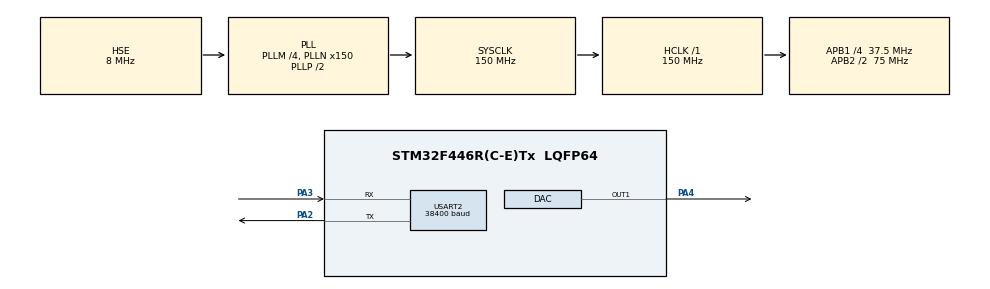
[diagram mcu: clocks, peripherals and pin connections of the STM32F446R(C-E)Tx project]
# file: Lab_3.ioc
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DAC.DAC_Trigger=DAC_TRIGGER_NONE
Mcu.Family=STM32F4
Mcu.Name=STM32F446R(C-E)Tx
Mcu.Package=LQFP64
NVIC.PriorityGroup=NVIC_PRIORITYGROUP_4
NVIC.TIM6_DAC_IRQn=true\:0\:0\:false\:false\:true\:true\:true\:true
NVIC.USART2_IRQn=true\:0\:0\:false\:false\:true\:true\:true\:true
PA2.Mode=Asynchronous
PA2.Signal=USART2_TX
PA3.Mode=Asynchronous
PA3.Signal=USART2_RX
PA4.Signal=COMP_DAC1_group
PH0-OSC_IN.Mode=HSE-External-Oscillator
PH0-OSC_IN.Signal=RCC_OSC_IN
PH1-OSC_OUT.Mode=HSE-External-Oscillator
PH1-OSC_OUT.Signal=RCC_OSC_OUT
ProjectManager.HeapSize=0x200
ProjectManager.StackSize=0x400
ProjectManager.TargetToolchain=STM32CubeIDE
RCC.AHBFreq_Value=150000000
RCC.APB1CLKDivider=RCC_HCLK_DIV4
RCC.APB1Freq_Value=37500000
RCC.APB1TimFreq_Value=75000000
RCC.APB2CLKDivider=RCC_HCLK_DIV2
RCC.APB2Freq_Value=75000000
RCC.APB2TimFreq_Value=150000000
RCC.CortexFreq_Value=150000000
RCC.HCLKFreq_Value=150000000
RCC.HSE_VALUE=8000000
RCC.PLLM=4
RCC.PLLN=150
RCC.PLLSourceVirtual=RCC_PLLSOURCE_HSE
RCC.SYSCLKFreq_VALUE=150000000
RCC.SYSCLKSource=RCC_SYSCLKSOURCE_PLLCLK
RCC.USBFreq_Value=150000000
RCC.VCOOutputFreq_Value=300000000
SH.COMP_DAC1_group.0=DAC_OUT1,DAC_OUT1
TIM6.Period=999
TIM6.Prescaler=74
USART2.BaudRate=38400
USART2.VirtualMode=VM_ASYNC
VP_TIM6_VS_ClockSourceINT.Mode=Enable_Timer
board=custom

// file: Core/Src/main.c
/* USER CODE BEGIN Header */
/**
  ******************************************************************************
  * @file           : main.c
  * @brief          : Main program body
  ******************************************************************************
  * @attention
  *
  * Copyright (c) 2024 STMicroelectronics.
  * All rights reserved.
  *
  * This software is licensed under terms that can be found in the LICENSE file
  * in the root directory of this software component.
  * If no LICENSE file comes with this software, it is provided AS-IS.
  *
  ******************************************************************************
  */
/* USER CODE END Header */
#include "main.h"

/* USER CODE BEGIN Includes */
#include "math.h"
#include "string.h"
/* USER CODE END Includes */

/* USER CODE BEGIN PD */
#define SAMPLE_RATE 1000
#define VREF 3.3f

#define COMMAND_SIZE 8
#define INVALID_COMMAND "INVALID_COMMAND"
#define SUCCESSFUL "SUCCESSFUL"
#define START_SYMBOL 'S'
#define END_SYMBOL 'E'
#define FREQUENCY_SYMBOL 'F'
#define AMPLITUDE_SYMBOL 'A'
/* USER CODE END PD */

DAC_HandleTypeDef hdac;

TIM_HandleTypeDef htim6;

UART_HandleTypeDef huart2;

/* USER CODE BEGIN PV */
uint16_t sine[SAMPLE_RATE];
uint16_t sample_index = 0;
float amplitude = 3.0f;
float offs = 0.0f;
float f = 10.0f;

uint8_t rxData[10];
/* USER CODE END PV */

void SystemClock_Config(void);
static void MX_GPIO_Init(void);
static void MX_DAC_Init(void);
static void MX_TIM6_Init(void);
static void MX_USART2_UART_Init(void);
/* USER CODE BEGIN PFP */
void generate_sin(float ampl, float offset, float freq);
void handle_invalid_command();
void handle_command(char* command);
/* USER CODE END PFP */

/* USER CODE BEGIN 0 */
void generate_sin(float ampl, float offset, float freq) {
	float omega = 2.0f * M_PI * freq / SAMPLE_RATE * 2;
	for (int i = 0; i < SAMPLE_RATE; i++) {
		float value = offset + ampl * sinf(omega * i);
		value = (value + ampl) / (2 * VREF);
		sine[i] = (uint16_t)(value * 4095);
	}
}

void HAL_TIM_PeriodElapsedCallback(TIM_HandleTypeDef *htim) {
	if (htim->Instance == TIM6) {
		HAL_DAC_SetValue(&hdac, DAC_CHANNEL_1, DAC_ALIGN_12B_R, sine[sample_index]);
		sample_index = (sample_index + 1) % SAMPLE_RATE;
	}
}

void handle_invalid_command() {
	HAL_UART_Transmit_IT(&huart2, (uint8_t *)INVALID_COMMAND, strlen(INVALID_COMMAND));
}

void handle_command(char* command) {
	if (command[0] == FREQUENCY_SYMBOL && command[4] == AMPLITUDE_SYMBOL) {
		f = (float)((command[1] - '0') * 100 + (command[2] - '0') * 10 + command[3] - '0');
		amplitude = command[5] - '0' + (command[7] - '0') * 0.1;
		if (amplitude > VREF) {
			amplitude = VREF;
		}
		generate_sin(amplitude, offs, f);
		HAL_UART_Transmit_IT(&huart2, (uint8_t *)SUCCESSFUL, strlen(SUCCESSFUL));
	} else {
		handle_invalid_command();
	}
}

void HAL_UART_RxCpltCallback(UART_HandleTypeDef *huart) {
	if (huart->Instance == USART2) {
		if (rxData[0] == START_SYMBOL && rxData[9] == END_SYMBOL) {
			char command[COMMAND_SIZE + 1];
			strncpy(command, (char *)&rxData[1], COMMAND_SIZE);
			command[COMMAND_SIZE] = '\0';
			handle_command(command);
		} else {
			handle_invalid_command();
		}
		memset(rxData, 0, sizeof(rxData));
		HAL_UART_Receive_IT(&huart2, rxData, sizeof(rxData));
	}
}
/* USER CODE END 0 */

int main(void)
{

  /* MCU Configuration--------------------------------------------------------*/

  /* Reset of all peripherals, Initializes the Flash interface and the Systick. */
  HAL_Init();

  /* Configure the system clock */
  SystemClock_Config();

  /* Initialize all configured peripherals */
  MX_GPIO_Init();
  MX_DAC_Init();
  MX_TIM6_Init();
  MX_USART2_UART_Init();
  /* USER CODE BEGIN 2 */
  if (amplitude > VREF) {
      amplitude = VREF;
  }
  generate_sin(amplitude, offs, f);

  HAL_TIM_Base_Start_IT(&htim6);
  HAL_UART_Receive_IT(&huart2, rxData, sizeof(rxData));
  HAL_DAC_Start(&hdac, DAC_CHANNEL_1);
  /* USER CODE END 2 */

  /* Infinite loop */
  while (1)
  {

  }
}

void SystemClock_Config(void)
{
  RCC_OscInitTypeDef RCC_OscInitStruct = {0};
  RCC_ClkInitTypeDef RCC_ClkInitStruct = {0};

  /** Configure the main internal regulator output voltage
  */
  __HAL_RCC_PWR_CLK_ENABLE();
  __HAL_PWR_VOLTAGESCALING_CONFIG(PWR_REGULATOR_VOLTAGE_SCALE1);

  /** Initializes the RCC Oscillators according to the specified parameters
  * in the RCC_OscInitTypeDef structure.
  */
  RCC_OscInitStruct.OscillatorType = RCC_OSCILLATORTYPE_HSE;
  RCC_OscInitStruct.HSEState = RCC_HSE_ON;
  RCC_OscInitStruct.PLL.PLLState = RCC_PLL_ON;
  RCC_OscInitStruct.PLL.PLLSource = RCC_PLLSOURCE_HSE;
  RCC_OscInitStruct.PLL.PLLM = 4;
  RCC_OscInitStruct.PLL.PLLN = 150;
  RCC_OscInitStruct.PLL.PLLP = RCC_PLLP_DIV2;
  RCC_OscInitStruct.PLL.PLLQ = 2;
  RCC_OscInitStruct.PLL.PLLR = 2;
  if (HAL_RCC_OscConfig(&RCC_OscInitStruct) != HAL_OK)
  {
    Error_Handler();
  }

  /** Initializes the CPU, AHB and APB buses clocks
  */
  RCC_ClkInitStruct.ClockType = RCC_CLOCKTYPE_HCLK|RCC_CLOCKTYPE_SYSCLK
                              |RCC_CLOCKTYPE_PCLK1|RCC_CLOCKTYPE_PCLK2;
  RCC_ClkInitStruct.SYSCLKSource = RCC_SYSCLKSOURCE_PLLCLK;
  RCC_ClkInitStruct.AHBCLKDivider = RCC_SYSCLK_DIV1;
  RCC_ClkInitStruct.APB1CLKDivider = RCC_HCLK_DIV4;
  RCC_ClkInitStruct.APB2CLKDivider = RCC_HCLK_DIV2;

  if (HAL_RCC_ClockConfig(&RCC_ClkInitStruct, FLASH_LATENCY_4) != HAL_OK)
  {
    Error_Handler();
  }
}

static void MX_DAC_Init(void)
{

  DAC_ChannelConfTypeDef sConfig = {0};

  /** DAC Initialization
  */
  hdac.Instance = DAC;
  if (HAL_DAC_Init(&hdac) != HAL_OK)
  {
    Error_Handler();
  }

  /** DAC channel OUT1 config
  */
  sConfig.DAC_Trigger = DAC_TRIGGER_NONE;
  sConfig.DAC_OutputBuffer = DAC_OUTPUTBUFFER_ENABLE;
  if (HAL_DAC_ConfigChannel(&hdac, &sConfig, DAC_CHANNEL_1) != HAL_OK)
  {
    Error_Handler();
  }

}

static void MX_TIM6_Init(void)
{

  TIM_MasterConfigTypeDef sMasterConfig = {0};

  htim6.Instance = TIM6;
  htim6.Init.Prescaler = 74;
  htim6.Init.CounterMode = TIM_COUNTERMODE_UP;
  htim6.Init.Period = 999;
  htim6.Init.AutoReloadPreload = TIM_AUTORELOAD_PRELOAD_DISABLE;
  if (HAL_TIM_Base_Init(&htim6) != HAL_OK)
  {
    Error_Handler();
  }
  sMasterConfig.MasterOutputTrigger = TIM_TRGO_RESET;
  sMasterConfig.MasterSlaveMode = TIM_MASTERSLAVEMODE_DISABLE;
  if (HAL_TIMEx_MasterConfigSynchronization(&htim6, &sMasterConfig) != HAL_OK)
  {
    Error_Handler();
  }

}

static void MX_USART2_UART_Init(void)
{

  huart2.Instance = USART2;
  huart2.Init.BaudRate = 38400;
  huart2.Init.WordLength = UART_WORDLENGTH_8B;
  huart2.Init.StopBits = UART_STOPBITS_1;
  huart2.Init.Parity = UART_PARITY_NONE;
  huart2.Init.Mode = UART_MODE_TX_RX;
  huart2.Init.HwFlowCtl = UART_HWCONTROL_NONE;
  huart2.Init.OverSampling = UART_OVERSAMPLING_16;
  if (HAL_UART_Init(&huart2) != HAL_OK)
  {
    Error_Handler();
  }

}

static void MX_GPIO_Init(void)
{

  /* GPIO Ports Clock Enable */
  __HAL_RCC_GPIOH_CLK_ENABLE();
  __HAL_RCC_GPIOA_CLK_ENABLE();

}

void Error_Handler(void)
{
  __disable_irq();
  while (1)
  {
  }
}
